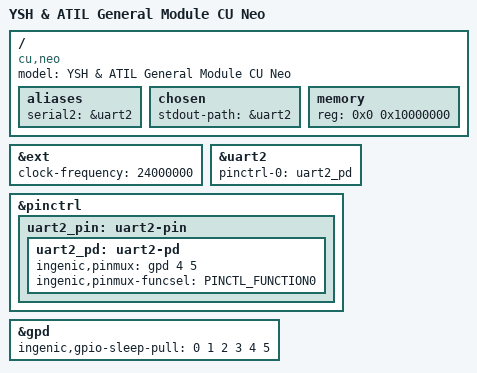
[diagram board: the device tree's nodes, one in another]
// SPDX-License-Identifier: GPL-2.0
/dts-v1/;

#include "x1000.dtsi"
#include <dt-bindings/gpio/gpio.h>
#include <dt-bindings/pinctrl/ingenic-pinctrl.h>

/ {
	model = "YSH & ATIL General Module CU Neo";
	compatible = "cu,neo", "ingenic,x1000";

	aliases {
		serial2 = &uart2;
	};

	chosen {
		stdout-path = &uart2;
	};

	memory {
		device_type = "memory";
		reg = <0x0 0x10000000>;
	};
};

&ext {
	clock-frequency = <24000000>;
};

&uart2 {
	status = "okay";

	pinctrl-names = "default";
	pinctrl-0 = <&uart2_pd>;
};

&pinctrl {
	uart2_pin: uart2-pin {
		uart2_pd: uart2-pd {
			ingenic,pinmux = <&gpd 4 5>;
			ingenic,pinmux-funcsel = <PINCTL_FUNCTION0>;
		};
	};
};

&gpd {
	ingenic,gpio-sleep-pull = <0 1 2 3 4 5>;
};

